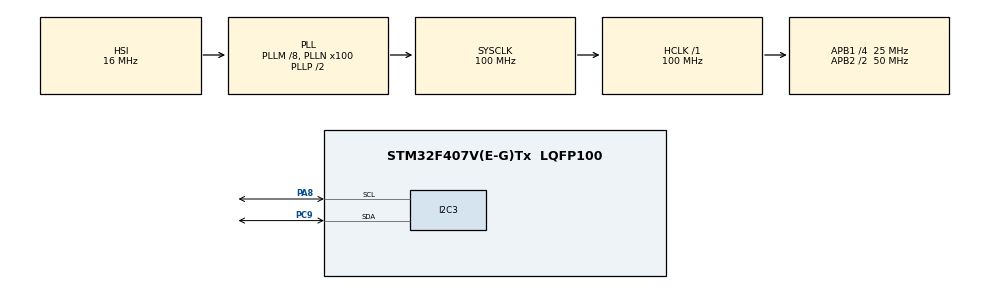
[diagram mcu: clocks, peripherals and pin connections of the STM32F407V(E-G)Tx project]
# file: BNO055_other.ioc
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Mcu.Family=STM32F4
Mcu.Name=STM32F407V(E-G)Tx
Mcu.Package=LQFP100
NVIC.PriorityGroup=NVIC_PRIORITYGROUP_0
PA13.Mode=Serial_Wire
PA13.Signal=SYS_JTMS-SWDIO
PA14.Mode=Serial_Wire
PA14.Signal=SYS_JTCK-SWCLK
PA8.Mode=I2C
PA8.Signal=I2C3_SCL
PC9.Mode=I2C
PC9.Signal=I2C3_SDA
ProjectManager.HeapSize=0x200
ProjectManager.StackSize=0x400
ProjectManager.TargetToolchain=STM32CubeIDE
RCC.48MHZClocksFreq_Value=28571428.57142857
RCC.AHBFreq_Value=100000000
RCC.APB1CLKDivider=RCC_HCLK_DIV4
RCC.APB1Freq_Value=25000000
RCC.APB1TimFreq_Value=50000000
RCC.APB2CLKDivider=RCC_HCLK_DIV2
RCC.APB2Freq_Value=50000000
RCC.APB2TimFreq_Value=100000000
RCC.CortexFreq_Value=100000000
RCC.HCLKFreq_Value=100000000
RCC.HSE_VALUE=8000000
RCC.HSI_VALUE=16000000
RCC.LSE_VALUE=32768
RCC.PLLM=8
RCC.PLLN=100
RCC.PLLQ=7
RCC.SYSCLKFreq_VALUE=100000000
RCC.SYSCLKSource=RCC_SYSCLKSOURCE_PLLCLK
RCC.VCOOutputFreq_Value=200000000
board=STM32F407G-DISC1

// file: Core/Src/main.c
/* USER CODE BEGIN Header */
/**
  ******************************************************************************
  * @file           : main.c
  * @brief          : Main program body
  ******************************************************************************
  * @attention
  *
  * Copyright (c) 2023 STMicroelectronics.
  * All rights reserved.
  *
  * This software is licensed under terms that can be found in the LICENSE file
  * in the root directory of this software component.
  * If no LICENSE file comes with this software, it is provided AS-IS.
  *
  ******************************************************************************
  */
/* USER CODE END Header */
#include "main.h"

/* USER CODE BEGIN Includes */
#include "bno055_stm32.h"

HAL_StatusTypeDef cnt;
/* USER CODE END Includes */

I2C_HandleTypeDef hi2c3;

void SystemClock_Config(void);
static void MX_I2C3_Init(void);

/* USER CODE BEGIN 0 */
int KX,KY,KZ;
int syst,gyr,magno,acc;
int bno_calib_setting = 1;
int bno_calib_complate = 1;
/* USER CODE END 0 */

int main(void)
{

  /* MCU Configuration--------------------------------------------------------*/

  /* Reset of all peripherals, Initializes the Flash interface and the Systick. */
  HAL_Init();

  /* Configure the system clock */
  SystemClock_Config();

  /* Initialize all configured peripherals */
  MX_I2C3_Init();
  /* USER CODE BEGIN 2 */
  bno055_setup();
  bno055_setOperationModeNDOF();

  /* USER CODE END 2 */

  /* Infinite loop */
  while (1)
  {

    /* USER CODE BEGIN 3 */

	  bno055_calibration_state_t calibstates = bno055_getCalibrationState();
	  syst = calibstates.accel;
	  gyr = calibstates.gyro;
	  magno = calibstates.mag;
	  acc = calibstates.sys;

	  if(bno_calib_setting == 1 && calibstates.accel==3 && calibstates.gyro==3 && calibstates.mag==3 && calibstates.sys==3)
	  {
		  bno055_setOperationMode(BNO055_OPERATION_MODE_CONFIG);
		  bno055_calibration_data_t calibdatas = bno055_getCalibrationData();
		  bno055_setCalibrationData(calibdatas);
		  bno_calib_complate = 2;
		  bno_calib_setting = 2;
		  bno055_setOperationMode(BNO055_OPERATION_MODE_NDOF);
	  }

if(bno_calib_complate == 2)
{
	  bno055_vector_t v = bno055_getVectorEuler();
	  	  	KZ=v.x;
	  	  	KY=v.y;
	  	  	KX=v.z;
}
  }
  /* USER CODE END 3 */
}

void SystemClock_Config(void)
{
  RCC_OscInitTypeDef RCC_OscInitStruct = {0};
  RCC_ClkInitTypeDef RCC_ClkInitStruct = {0};

  /** Configure the main internal regulator output voltage
  */
  __HAL_RCC_PWR_CLK_ENABLE();
  __HAL_PWR_VOLTAGESCALING_CONFIG(PWR_REGULATOR_VOLTAGE_SCALE1);

  /** Initializes the RCC Oscillators according to the specified parameters
  * in the RCC_OscInitTypeDef structure.
  */
  RCC_OscInitStruct.OscillatorType = RCC_OSCILLATORTYPE_HSI;
  RCC_OscInitStruct.HSIState = RCC_HSI_ON;
  RCC_OscInitStruct.HSICalibrationValue = RCC_HSICALIBRATION_DEFAULT;
  RCC_OscInitStruct.PLL.PLLState = RCC_PLL_ON;
  RCC_OscInitStruct.PLL.PLLSource = RCC_PLLSOURCE_HSI;
  RCC_OscInitStruct.PLL.PLLM = 8;
  RCC_OscInitStruct.PLL.PLLN = 100;
  RCC_OscInitStruct.PLL.PLLP = RCC_PLLP_DIV2;
  RCC_OscInitStruct.PLL.PLLQ = 7;
  if (HAL_RCC_OscConfig(&RCC_OscInitStruct) != HAL_OK)
  {
    Error_Handler();
  }

  /** Initializes the CPU, AHB and APB buses clocks
  */
  RCC_ClkInitStruct.ClockType = RCC_CLOCKTYPE_HCLK|RCC_CLOCKTYPE_SYSCLK
                              |RCC_CLOCKTYPE_PCLK1|RCC_CLOCKTYPE_PCLK2;
  RCC_ClkInitStruct.SYSCLKSource = RCC_SYSCLKSOURCE_PLLCLK;
  RCC_ClkInitStruct.AHBCLKDivider = RCC_SYSCLK_DIV1;
  RCC_ClkInitStruct.APB1CLKDivider = RCC_HCLK_DIV4;
  RCC_ClkInitStruct.APB2CLKDivider = RCC_HCLK_DIV2;

  if (HAL_RCC_ClockConfig(&RCC_ClkInitStruct, FLASH_LATENCY_3) != HAL_OK)
  {
    Error_Handler();
  }
}

static void MX_I2C3_Init(void)
{

  hi2c3.Instance = I2C3;
  hi2c3.Init.ClockSpeed = 100000;
  hi2c3.Init.DutyCycle = I2C_DUTYCYCLE_2;
  hi2c3.Init.OwnAddress1 = 0;
  hi2c3.Init.AddressingMode = I2C_ADDRESSINGMODE_7BIT;
  hi2c3.Init.DualAddressMode = I2C_DUALADDRESS_DISABLE;
  hi2c3.Init.OwnAddress2 = 0;
  hi2c3.Init.GeneralCallMode = I2C_GENERALCALL_DISABLE;
  hi2c3.Init.NoStretchMode = I2C_NOSTRETCH_DISABLE;
  if (HAL_I2C_Init(&hi2c3) != HAL_OK)
  {
    Error_Handler();
  }

}

void Error_Handler(void)
{
  __disable_irq();
  while (1)
  {
  }
}
